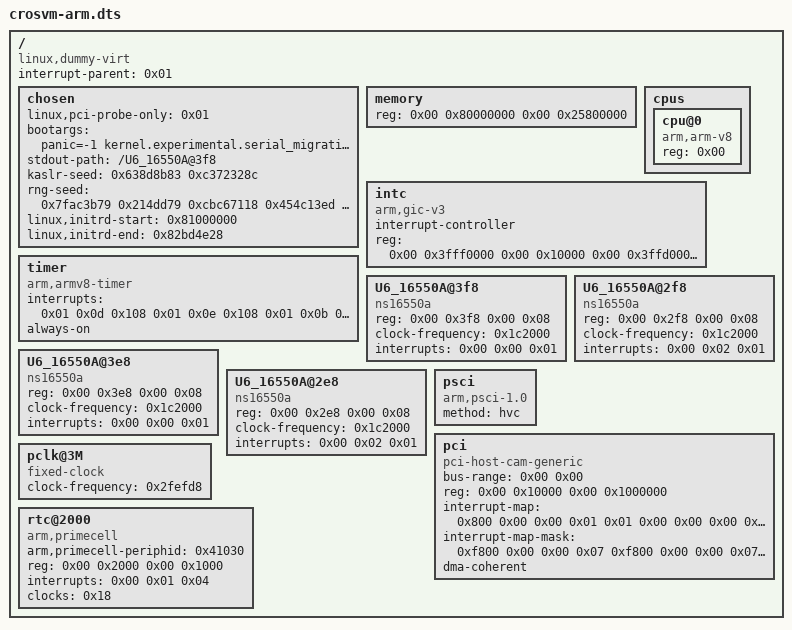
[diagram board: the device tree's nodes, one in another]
/dts-v1/;

/ {
        interrupt-parent = <0x01>;
        compatible = "linux,dummy-virt";
        #address-cells = <0x02>;
        #size-cells = <0x02>;

        chosen {
                linux,pci-probe-only = <0x01>;
                bootargs = "panic=-1 kernel.experimental.serial_migration=true console.shell=true zircon.autorun.boot=/boot/bin/devicetree-extract";
                stdout-path = "/U6_16550A@3f8";
                kaslr-seed = <0x638d8b83 0xc372328c>;
                rng-seed = <0x7fac3b79 0x214dd79 0xcbc67118 0x454c13ed 0x1fb43cd3 0x7cc83e0b 0x5050860f 0x4c24c33f 0xd7c3d066 0x9aead4ae 0x576fa09a 0xc9c09431 0x114a9f9 0xfff84944 0xcda53d73 0x4e8a1e03 0x1ba8c6cd 0x46c7542d 0x69aba8f 0x45542437 0x6c53f034 0x757a34ce 0xdc55b26b 0xf5ba32c0 0xa45f6db5 0x29d02091 0xfbda96cf 0x97955c25 0x6c9d9cb3 0xc3793202 0xa0bde7bd 0xbdeb2d91 0x5205faef 0xce8b8596 0xd66686f 0x9916e9cf 0x661205ef 0x9ba52e4d 0x91558163 0x3a59b735 0xaf9d843a 0x1ff3371f 0xe949b186 0xa6125dc 0x23ffd6d6 0x701c8590 0x80b4001f 0x32c142b6 0xc09dc4d1 0xb29a309f 0xc1d5685d 0x8cd3f21f 0xecd1656a 0xc3490d7f 0x91fc3f99 0x1c6a16da 0x3dd006cf 0x84cc4b93 0xb31b7d9e 0x2b85e64f 0x9fbe382e 0xb6a59f64 0xff2d0974 0xf1620540>;
                linux,initrd-start = <0x81000000>;
                linux,initrd-end = <0x82bd4e28>;
        };

        memory {
                device_type = "memory";
                reg = <0x00 0x80000000 0x00 0x25800000>;
        };

        cpus {
                #address-cells = <0x01>;
                #size-cells = <0x00>;

                cpu@0 {
                        device_type = "cpu";
                        compatible = "arm,arm-v8";
                        reg = <0x00>;
                        phandle = <0x100>;
                };
        };

        intc {
                compatible = "arm,gic-v3";
                #interrupt-cells = <0x03>;
                interrupt-controller;
                reg = <0x00 0x3fff0000 0x00 0x10000 0x00 0x3ffd0000 0x00 0x20000>;
                phandle = <0x01>;
                #address-cells = <0x02>;
                #size-cells = <0x02>;
        };

        timer {
                compatible = "arm,armv8-timer";
                interrupts = <0x01 0x0d 0x108 0x01 0x0e 0x108 0x01 0x0b 0x108 0x01 0x0a 0x108>;
                always-on;
        };

        U6_16550A@3f8 {
                compatible = "ns16550a";
                reg = <0x00 0x3f8 0x00 0x08>;
                clock-frequency = <0x1c2000>;
                interrupts = <0x00 0x00 0x01>;
        };

        U6_16550A@2f8 {
                compatible = "ns16550a";
                reg = <0x00 0x2f8 0x00 0x08>;
                clock-frequency = <0x1c2000>;
                interrupts = <0x00 0x02 0x01>;
        };

        U6_16550A@3e8 {
                compatible = "ns16550a";
                reg = <0x00 0x3e8 0x00 0x08>;
                clock-frequency = <0x1c2000>;
                interrupts = <0x00 0x00 0x01>;
        };

        U6_16550A@2e8 {
                compatible = "ns16550a";
                reg = <0x00 0x2e8 0x00 0x08>;
                clock-frequency = <0x1c2000>;
                interrupts = <0x00 0x02 0x01>;
        };

        psci {
                compatible = "arm,psci-1.0\0arm,psci-0.2";
                method = "hvc";
        };

        pci {
                compatible = "pci-host-cam-generic";
                device_type = "pci";
                ranges = <0x3000000 0x00 0x2000000 0x00 0x2000000 0x00 0x2000000 0x3000000 0x00 0xa6000000 0x00 0xa6000000 0xff 0x5a000000>;
                bus-range = <0x00 0x00>;
                #address-cells = <0x03>;
                #size-cells = <0x02>;
                reg = <0x00 0x10000 0x00 0x1000000>;
                #interrupt-cells = <0x01>;
                interrupt-map = <0x800 0x00 0x00 0x01 0x01 0x00 0x00 0x00 0x03 0x04 0x1000 0x00 0x00 0x01 0x01 0x00 0x00 0x00 0x04 0x04 0x1800 0x00 0x00 0x01 0x01 0x00 0x00 0x00 0x05 0x04 0x2000 0x00 0x00 0x01 0x01 0x00 0x00 0x00 0x06 0x04 0x2800 0x00 0x00 0x01 0x01 0x00 0x00 0x00 0x07 0x04 0x3000 0x00 0x00 0x01 0x01 0x00 0x00 0x00 0x08 0x04 0x3800 0x00 0x00 0x01 0x01 0x00 0x00 0x00 0x09 0x04>;
                interrupt-map-mask = <0xf800 0x00 0x00 0x07 0xf800 0x00 0x00 0x07 0xf800 0x00 0x00 0x07 0xf800 0x00 0x00 0x07 0xf800 0x00 0x00 0x07 0xf800 0x00 0x00 0x07 0xf800 0x00 0x00 0x07>;
                dma-coherent;
        };

        pclk@3M {
                #clock-cells = <0x00>;
                compatible = "fixed-clock";
                clock-frequency = <0x2fefd8>;
                phandle = <0x18>;
        };

        rtc@2000 {
                compatible = "arm,primecell";
                arm,primecell-periphid = <0x41030>;
                reg = <0x00 0x2000 0x00 0x1000>;
                interrupts = <0x00 0x01 0x04>;
                clocks = <0x18>;
                clock-names = "apb_pclk";
        };
};
